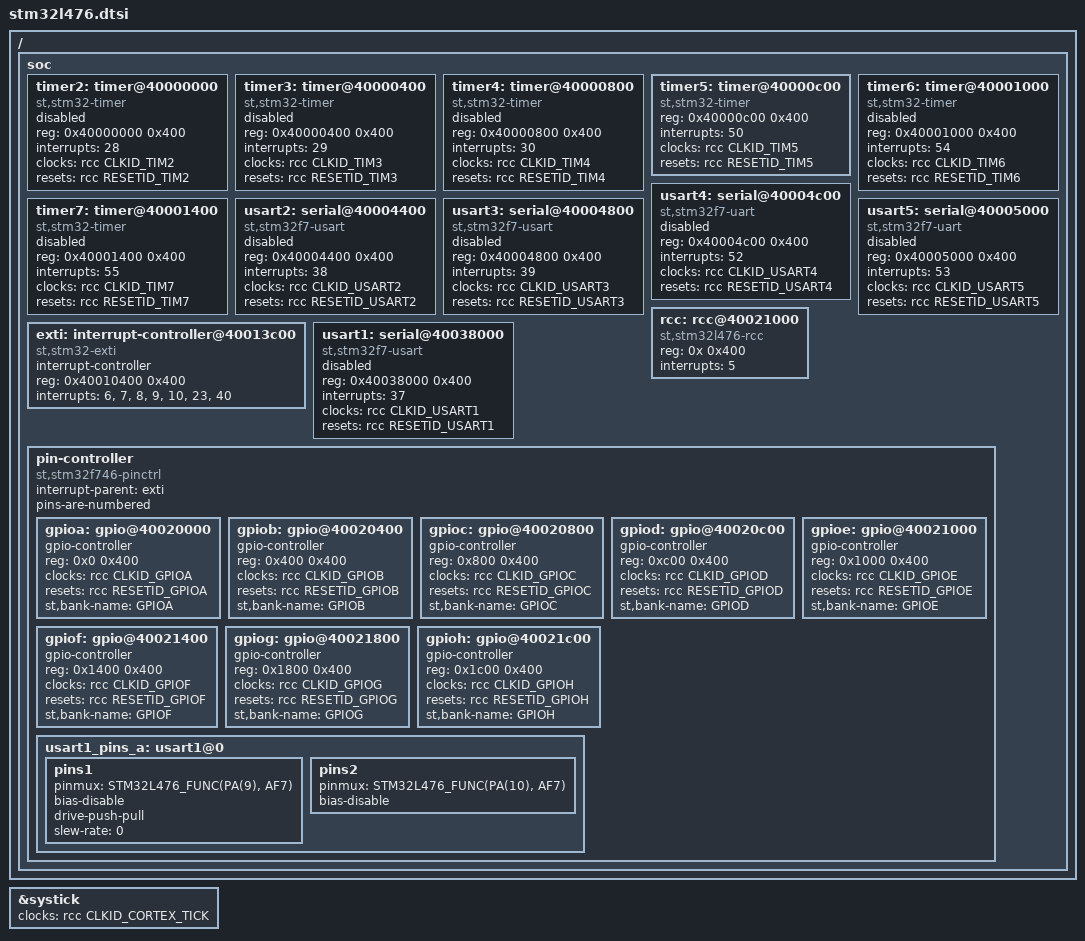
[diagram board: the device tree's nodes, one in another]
/*
 * Copyright 2017 BayLibre, SAS
 * Author: Neil Armstrong <narmstrong@baylibre.com>
 *
 * This file is dual-licensed: you can use it either under the terms
 * of the GPL or the X11 license, at your option. Note that this dual
 * licensing only applies to this file, and not this project as a
 * whole.
 *
 *  a) This file is free software; you can redistribute it and/or
 *     modify it under the terms of the GNU General Public License as
 *     published by the Free Software Foundation; either version 2 of the
 *     License, or (at your option) any later version.
 *
 *     This file is distributed in the hope that it will be useful,
 *     but WITHOUT ANY WARRANTY; without even the implied warranty of
 *     MERCHANTABILITY or FITNESS FOR A PARTICULAR PURPOSE.  See the
 *     GNU General Public License for more details.
 *
 * Or, alternatively,
 *
 *  b) Permission is hereby granted, free of charge, to any person
 *     obtaining a copy of this software and associated documentation
 *     files (the "Software"), to deal in the Software without
 *     restriction, including without limitation the rights to use,
 *     copy, modify, merge, publish, distribute, sublicense, and/or
 *     sell copies of the Software, and to permit persons to whom the
 *     Software is furnished to do so, subject to the following
 *     conditions:
 *
 *     The above copyright notice and this permission notice shall be
 *     included in all copies or substantial portions of the Software.
 *
 *     THE SOFTWARE IS PROVIDED "AS IS", WITHOUT WARRANTY OF ANY KIND,
 *     EXPRESS OR IMPLIED, INCLUDING BUT NOT LIMITED TO THE WARRANTIES
 *     OF MERCHANTABILITY, FITNESS FOR A PARTICULAR PURPOSE AND
 *     NONINFRINGEMENT. IN NO EVENT SHALL THE AUTHORS OR COPYRIGHT
 *     HOLDERS BE LIABLE FOR ANY CLAIM, DAMAGES OR OTHER LIABILITY,
 *     WHETHER IN AN ACTION OF CONTRACT, TORT OR OTHERWISE, ARISING
 *     FROM, OUT OF OR IN CONNECTION WITH THE SOFTWARE OR THE USE OR
 *     OTHER DEALINGS IN THE SOFTWARE.
 */

#include "skeleton.dtsi"
#include "armv7-m.dtsi"
#include <dt-bindings/pinctrl/stm32l746-pinfunc.h>
#include <dt-bindings/clock/stm32l746-clock.h>
#include <dt-bindings/reset/stm32l746-reset.h>

/ {
	soc {
		timer2: timer@40000000 {
			compatible = "st,stm32-timer";
			reg = <0x40000000 0x400>;
			interrupts = <28>;
			clocks = <&rcc CLKID_TIM2>;
			resets = <&rcc RESETID_TIM2>;
			status = "disabled";
		};

		timer3: timer@40000400 {
			compatible = "st,stm32-timer";
			reg = <0x40000400 0x400>;
			interrupts = <29>;
			clocks = <&rcc CLKID_TIM3>;
			resets = <&rcc RESETID_TIM3>;
			status = "disabled";
		};

		timer4: timer@40000800 {
			compatible = "st,stm32-timer";
			reg = <0x40000800 0x400>;
			interrupts = <30>;
			clocks = <&rcc CLKID_TIM4>;
			resets = <&rcc RESETID_TIM4>;
			status = "disabled";
		};

		timer5: timer@40000c00 {
			compatible = "st,stm32-timer";
			reg = <0x40000c00 0x400>;
			interrupts = <50>;
			clocks = <&rcc CLKID_TIM5>;
			resets = <&rcc RESETID_TIM5>;
		};

		timer6: timer@40001000 {
			compatible = "st,stm32-timer";
			reg = <0x40001000 0x400>;
			interrupts = <54>;
			clocks = <&rcc CLKID_TIM6>;
			resets = <&rcc RESETID_TIM6>;
			status = "disabled";
		};

		timer7: timer@40001400 {
			compatible = "st,stm32-timer";
			reg = <0x40001400 0x400>;
			interrupts = <55>;
			clocks = <&rcc CLKID_TIM7>;
			resets = <&rcc RESETID_TIM7>;
			status = "disabled";
		};

		usart2: serial@40004400 {
			compatible = "st,stm32f7-usart", "st,stm32f7-uart";
			reg = <0x40004400 0x400>;
			interrupts = <38>;
			clocks =  <&rcc CLKID_USART2>;
			resets = <&rcc RESETID_USART2>;
			status = "disabled";
		};

		usart3: serial@40004800 {
			compatible = "st,stm32f7-usart", "st,stm32f7-uart";
			reg = <0x40004800 0x400>;
			interrupts = <39>;
			clocks = <&rcc CLKID_USART3>;
			resets = <&rcc RESETID_USART3>;
			status = "disabled";
		};

		usart4: serial@40004c00 {
			compatible = "st,stm32f7-uart";
			reg = <0x40004c00 0x400>;
			interrupts = <52>;
			clocks = <&rcc CLKID_USART4>;
			resets = <&rcc RESETID_USART4>;
			status = "disabled";
		};

		usart5: serial@40005000 {
			compatible = "st,stm32f7-uart";
			reg = <0x40005000 0x400>;
			interrupts = <53>;
			clocks = <&rcc CLKID_USART5>;
			resets = <&rcc RESETID_USART5>;
			status = "disabled";
		};

		exti: interrupt-controller@40013c00 {
			compatible = "st,stm32-exti";
			interrupt-controller;
			#interrupt-cells = <2>;
			reg = <0x40010400 0x400>;
			interrupts = <6>, <7>, <8>, <9>, <10>, <23>, <40>;
		};

		rcc: rcc@40021000 {
			#clock-cells = <1>;
			#reset-cells = <1>;
			compatible = "st,stm32l476-rcc", "st,stm32-rcc";
			reg = <0x 0x400>;
			interrupts = <5>;
		};

		usart1: serial@40038000 {
			compatible = "st,stm32f7-usart", "st,stm32f7-uart";
			reg = <0x40038000 0x400>;
			interrupts = <37>;
			clocks = <&rcc CLKID_USART1>;
			resets = <&rcc RESETID_USART1>;
			status = "disabled";
		};

		pin-controller {
			#address-cells = <1>;
			#size-cells = <1>;
			compatible = "st,stm32f746-pinctrl";
			ranges = <0 0x48000000 0x2000>;
			interrupt-parent = <&exti>;
			pins-are-numbered;

			gpioa: gpio@40020000 {
				gpio-controller;
				#gpio-cells = <2>;
				reg = <0x0 0x400>;
				clocks = <&rcc CLKID_GPIOA>;
				resets = <&rcc RESETID_GPIOA>;
				st,bank-name = "GPIOA";
			};

			gpiob: gpio@40020400 {
				gpio-controller;
				#gpio-cells = <2>;
				reg = <0x400 0x400>;
				clocks = <&rcc CLKID_GPIOB>;
				resets = <&rcc RESETID_GPIOB>;
				st,bank-name = "GPIOB";
			};

			gpioc: gpio@40020800 {
				gpio-controller;
				#gpio-cells = <2>;
				reg = <0x800 0x400>;
				clocks = <&rcc CLKID_GPIOC>;
				resets = <&rcc RESETID_GPIOC>;
				st,bank-name = "GPIOC";
			};

			gpiod: gpio@40020c00 {
				gpio-controller;
				#gpio-cells = <2>;
				reg = <0xc00 0x400>;
				clocks = <&rcc CLKID_GPIOD>;
				resets = <&rcc RESETID_GPIOD>;
				st,bank-name = "GPIOD";
			};

			gpioe: gpio@40021000 {
				gpio-controller;
				#gpio-cells = <2>;
				reg = <0x1000 0x400>;
				clocks = <&rcc CLKID_GPIOE>;
				resets = <&rcc RESETID_GPIOE>;
				st,bank-name = "GPIOE";
			};

			gpiof: gpio@40021400 {
				gpio-controller;
				#gpio-cells = <2>;
				reg = <0x1400 0x400>;
				clocks = <&rcc CLKID_GPIOF>;
				resets = <&rcc RESETID_GPIOF>;
				st,bank-name = "GPIOF";
			};

			gpiog: gpio@40021800 {
				gpio-controller;
				#gpio-cells = <2>;
				reg = <0x1800 0x400>;
				clocks = <&rcc CLKID_GPIOG>;
				resets = <&rcc RESETID_GPIOG>;
				st,bank-name = "GPIOG";
			};

			gpioh: gpio@40021c00 {
				gpio-controller;
				#gpio-cells = <2>;
				reg = <0x1c00 0x400>;
				clocks = <&rcc CLKID_GPIOH>;
				resets = <&rcc RESETID_GPIOH>;
				st,bank-name = "GPIOH";
			};

			usart1_pins_a: usart1@0 {
				pins1 {
					pinmux = <STM32L476_FUNC(PA(9), AF7)>;
					bias-disable;
					drive-push-pull;
					slew-rate = <0>;
				};
				pins2 {
					pinmux = <STM32L476_FUNC(PA(10), AF7)>;
					bias-disable;
				};
			};
		};
	};
};

&systick {
	clocks = <&rcc CLKID_CORTEX_TICK>;
	status = "okay";
};
